AUTOSAR XML (schema 321)
package /ComponentType
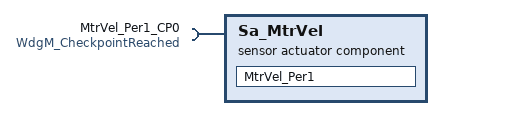
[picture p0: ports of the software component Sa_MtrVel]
  sensor actuator software component type Sa_MtrVel
    require port MtrVel_Per1_CP0: client-com-spec=CheckpointReached, required-interface=WdgM_CheckpointReached
  internal behavior Sa_MtrVel_InternalBehavior: component=Sa_MtrVel, port-api-option{enable-take-address=false, indirect-api=false, port=MtrVel_Per1_CP0}
    runnable MtrVel_Per1
      sync call SC_MtrVel_Per1_CP0_CheckpointReached: operation=MtrVel_Per1_CP0.CheckpointReached, timeout=0
  swc implementation Sa_MtrVel_Implementation: behavior=Sa_MtrVel_InternalBehavior
    code-descriptors:
      code Code: type=SRC
package /PortInterface
  client server interface WdgM_CheckpointReached: is-service=true
    operation CheckpointReached: possible-error=E_NOT_OK  # Indicates to the Watchdog Manager that a Checkpoint within a Supervised Entity has been reached.
    error E_NOT_OK: error-code=1
